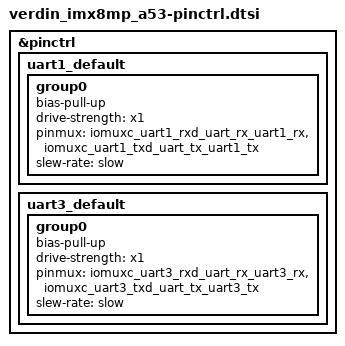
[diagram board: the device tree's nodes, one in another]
/*
 * SPDX-License-Identifier: Apache-2.0
 * SPDX-FileCopyrightText: 2026 Signal Slot, Inc.
 *
 * Pins the A53 side of the Verdin iMX8M Plus uses. UART3 is Verdin UART_1
 * (SODIMM 147/149), the Linux console on Torizon.
 */

#include <nxp/nxp_imx/mimx8ml8dvnlz-pinctrl.dtsi>

&pinctrl {
	/* UART1 on its own pads: the Mallow's X11 header. */
	uart1_default: uart1_default {
		group0 {
			bias-pull-up;
			drive-strength = "x1";
			pinmux = <&iomuxc_uart1_rxd_uart_rx_uart1_rx>,
				 <&iomuxc_uart1_txd_uart_tx_uart1_tx>;
			slew-rate = "slow";
		};
	};

	uart3_default: uart3_default {
		group0 {
			bias-pull-up;
			drive-strength = "x1";
			pinmux = <&iomuxc_uart3_rxd_uart_rx_uart3_rx>,
				 <&iomuxc_uart3_txd_uart_tx_uart3_tx>;
			slew-rate = "slow";
		};
	};
};
